# ATSAMG55G19 register map
Vendor: Atmel; Series: SAMG55; File version: 0
CPU: CM4 r0p1, selectable endian, MPU, FPU, 4 interrupt priority bits
Registers are 32-bit, read-write, reset 0x0 unless marked. A register's access mark holds for its fields unless they carry their own. Offsets are from the block's base; [hi:lo] are bit positions; {n}, {i} and the like mark numbered series.

## UDP — USB Device Port
Base 0x40044000; register names take the prefix UDP_
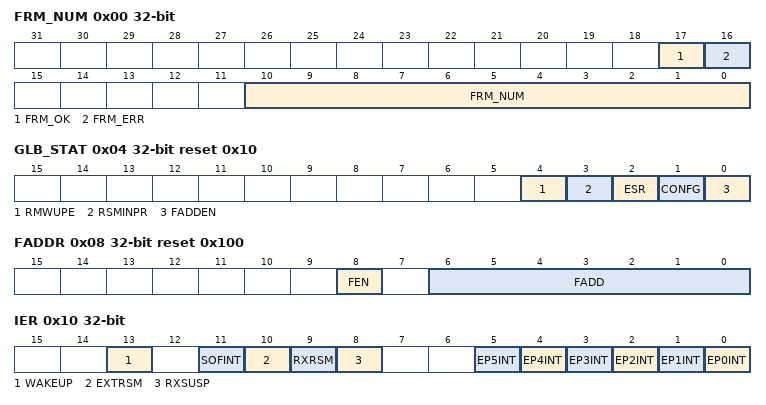
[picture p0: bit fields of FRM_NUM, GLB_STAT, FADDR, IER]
0x00 FRM_NUM ro — Frame Number Register
  [17] FRM_OK — Frame OK
  [16] FRM_ERR — Frame Error
  [10:0] FRM_NUM — Frame Number as Defined in the Packet Field Formats
0x04 GLB_STAT reset 0x10 — Global State Register
  [4] RMWUPE — Remote Wakeup Enable
  [3] RSMINPR
  [2] ESR — Enable Send Resume
  [1] CONFG — Configured
  [0] FADDEN — Function Address Enable
0x08 FADDR reset 0x100 — Function Address Register
  [8] FEN — Function Enable
  [6:0] FADD — Function Address Value
0x10 IER wo reset not defined — Interrupt Enable Register
  [13] WAKEUP — Enable UDP Bus Wakeup Interrupt
  [11] SOFINT — Enable Start Of Frame Interrupt
  [10] EXTRSM
  [9] RXRSM — Enable UDP Resume Interrupt
  [8] RXSUSP — Enable UDP Suspend Interrupt
  [5] EP5INT — Enable Endpoint 5 Interrupt
  [4] EP4INT — Enable Endpoint 4 Interrupt
  [3] EP3INT — Enable Endpoint 3 Interrupt
  [2] EP2INT — Enable Endpoint 2Interrupt
  [1] EP1INT — Enable Endpoint 1 Interrupt
  [0] EP0INT — Enable Endpoint 0 Interrupt
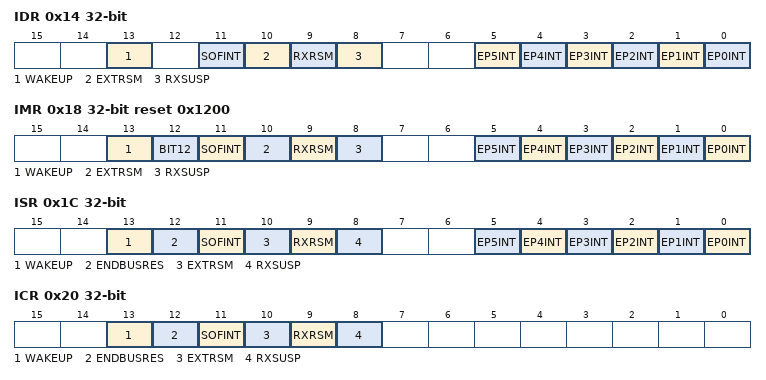
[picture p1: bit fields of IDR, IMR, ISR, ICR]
0x14 IDR wo reset not defined — Interrupt Disable Register
  [13] WAKEUP — Disable USB Bus Interrupt
  [11] SOFINT — Disable Start Of Frame Interrupt
  [10] EXTRSM
  [9] RXRSM — Disable UDP Resume Interrupt
  [8] RXSUSP — Disable UDP Suspend Interrupt
  [n] EP{n}INT (n=0..5) — Disable Endpoint {n} Interrupt
0x18 IMR ro reset 0x1200 — Interrupt Mask Register
  [13] WAKEUP — USB Bus Wakeup Interrupt
  [12] BIT12 — UDP_IMR Bit 12
  [11] SOFINT — Mask Start Of Frame Interrupt
  [10] EXTRSM
  [9] RXRSM — Mask UDP Resume Interrupt.
  [8] RXSUSP — Mask UDP Suspend Interrupt
  [n] EP{n}INT (n=0..5) — Mask Endpoint {n} Interrupt
0x1C ISR ro reset not defined — Interrupt Status Register
  [13] WAKEUP — UDP Resume Interrupt Status
  [12] ENDBUSRES — End of BUS Reset Interrupt Status
  [11] SOFINT — Start of Frame Interrupt Status
  [10] EXTRSM
  [9] RXRSM — UDP Resume Interrupt Status
  [8] RXSUSP — UDP Suspend Interrupt Status
  [n] EP{n}INT (n=0..5) — Endpoint {n} Interrupt Status
0x20 ICR wo reset not defined — Interrupt Clear Register
  [13] WAKEUP — Clear Wakeup Interrupt
  [12] ENDBUSRES — Clear End of Bus Reset Interrupt
  [11] SOFINT — Clear Start Of Frame Interrupt
  [10] EXTRSM
  [9] RXRSM — Clear UDP Resume Interrupt
  [8] RXSUSP — Clear UDP Suspend Interrupt
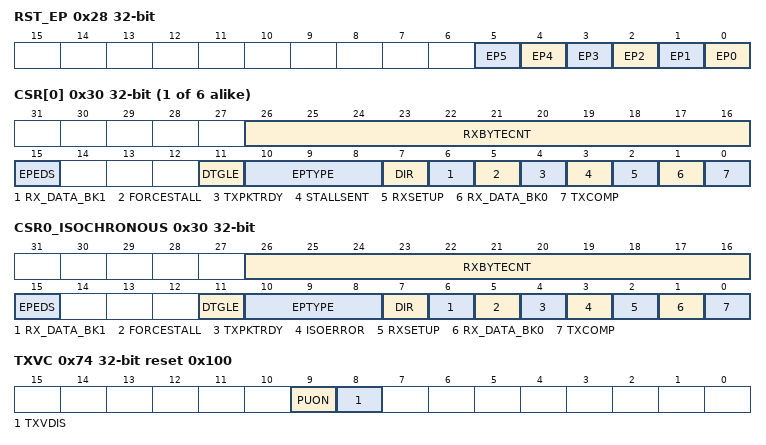
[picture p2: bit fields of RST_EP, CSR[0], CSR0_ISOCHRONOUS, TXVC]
0x28 RST_EP — Reset Endpoint Register
  [n] EP{n} (n=0..5) — Reset Endpoint {n}
{0x30+4i} CSR[{i}] (i=0..5) reset not defined — Endpoint Control and Status Register
  [26:16] RXBYTECNT — Number of Bytes Available in the FIFO (Read-only)
  [15] EPEDS — Endpoint Enable Disable
  [11] DTGLE — Data Toggle (Read-only)
  [10:8] EPTYPE — Endpoint Type (Read/Write)
    0=CTRL (Control); 1=ISO_OUT (Isochronous OUT); 2=BULK_OUT; 3=INT_OUT (Interrupt OUT); 5=ISO_IN (Isochronous IN); 6=BULK_IN; 7=INT_IN (Interrupt IN)
  [7] DIR — Transfer Direction (only available for control endpoints) (Read/Write)
  [6] RX_DATA_BK1 — Receive Data Bank 1 (only used by endpoints with ping-pong attributes)
  [5] FORCESTALL — Force Stall (used by Control, Bulk and Isochronous Endpoints)
  [4] TXPKTRDY — Transmit Packet Ready
  [3] STALLSENT
  [2] RXSETUP — Received Setup
  [1] RX_DATA_BK0 — Receive Data Bank 0
  [0] TXCOMP — Generates an IN Packet with Data Previously Written in the DPR
0x30 CSR0_ISOCHRONOUS reset not defined (ISOCHRONOUS view) — Endpoint Control and Status Register
  [26:16] RXBYTECNT — Number of Bytes Available in the FIFO (Read-only)
  [15] EPEDS — Endpoint Enable Disable
  [11] DTGLE — Data Toggle (Read-only)
  [10:8] EPTYPE — Endpoint Type (Read/Write)
    0=CTRL (Control); 1=ISO_OUT (Isochronous OUT); 5=ISO_IN (Isochronous IN); 2=BULK_OUT; 6=BULK_IN; 3=INT_OUT (Interrupt OUT); 7=INT_IN (Interrupt IN)
  [7] DIR — Transfer Direction (only available for control endpoints) (Read/Write)
  [6] RX_DATA_BK1 — Receive Data Bank 1 (only used by endpoints with ping-pong attributes)
  [5] FORCESTALL — Force Stall (used by Control, Bulk and Isochronous Endpoints)
  [4] TXPKTRDY — Transmit Packet Ready
  [3] ISOERROR — A CRC error has been detected in an isochronous transfer
  [2] RXSETUP — Received Setup
  [1] RX_DATA_BK0 — Receive Data Bank 0
  [0] TXCOMP — Generates an IN Packet with Data Previously Written in the DPR
{0x50+4i} FDR[{i}] (i=0..5) reset not defined — Endpoint FIFO Data Register
  [7:0] FIFO_DATA — FIFO Data Value
0x74 TXVC reset 0x100 — Transceiver Control Register
  [9] PUON — Pull-up On
  [8] TXVDIS — Transceiver Disable
